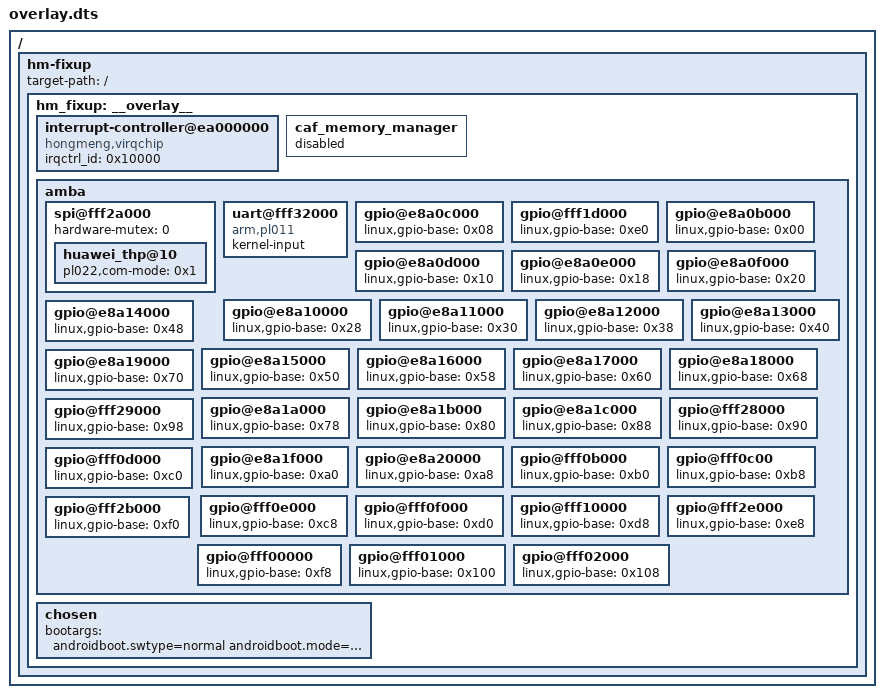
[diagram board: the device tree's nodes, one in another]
/dts-v1/;
/plugin/;

/* override conflict kirin980_chip_cs entries */
/ {
	hm-fixup {
		target-path = "/";
		hm_fixup: __overlay__ {};
	};
};

&hm_fixup {
	/* disable GIC to avoid hmkernel probe it */
	interrupt-controller@ea000000 {
		compatible = "hongmeng,virqchip";
		/* the value must be positive and the same as
		 * irqctrl_id in kirin980.dts
		 */
		irqctrl_id = <0x10000>;
	};

	/* disable mem manger for mali */
	caf_memory_manager {
		status = "disabled";
	};

	amba {
		/* disable un-supported features in thp spi */
		spi@fff2a000 {
			hardware-mutex = <0>; /* disable hardware mutex for spi3 */
			huawei_thp@10 {
				/* use polling mode instead of dma */
				pl022,com-mode = <0x1>;
			};
		};

		/* config uart6 as kernel-input */
		uart@fff32000 {
			compatible = "arm,pl011", "arm,pl011,uart";
			kernel-input;
		};

		/* config gpio base for backlight */
		gpio@e8a0c000 {
			linux,gpio-base = <0x08>;
		};

		gpio@fff1d000 {
			linux,gpio-base = <0xe0>;
		};

		/* config gpio base */
		gpio@e8a0b000 {
			linux,gpio-base = <0x00>;
		};

		gpio@e8a0d000 {
			linux,gpio-base = <0x10>;
		};

		gpio@e8a0e000 {
			linux,gpio-base = <0x18>;
		};

		gpio@e8a0f000 {
			linux,gpio-base = <0x20>;
		};

		gpio@e8a10000 {
			linux,gpio-base = <0x28>;
		};

		gpio@e8a11000 {
			linux,gpio-base = <0x30>;
		};

		gpio@e8a12000 {
			linux,gpio-base = <0x38>;
		};

		gpio@e8a13000 {
			linux,gpio-base = <0x40>;
		};

		gpio@e8a14000 {
			linux,gpio-base = <0x48>;
		};

		gpio@e8a15000 {
			linux,gpio-base = <0x50>;
		};

		gpio@e8a16000 {
			linux,gpio-base = <0x58>;
		};

		gpio@e8a17000 {
			linux,gpio-base = <0x60>;
		};

		gpio@e8a18000 {
			linux,gpio-base = <0x68>;
		};

		gpio@e8a19000 {
			linux,gpio-base = <0x70>;
		};

		gpio@e8a1a000 {
			linux,gpio-base = <0x78>;
		};

		gpio@e8a1b000 {
			linux,gpio-base = <0x80>;
		};

		gpio@e8a1c000 {
			linux,gpio-base = <0x88>;
		};

		gpio@fff28000 {
			linux,gpio-base = <0x90>;
		};

		gpio@fff29000 {
			linux,gpio-base = <0x98>;
		};

		gpio@e8a1f000 {
			linux,gpio-base = <0xa0>;
		};

		gpio@e8a20000 {
			linux,gpio-base = <0xa8>;
		};

		gpio@fff0b000 {
			linux,gpio-base = <0xb0>;
		};

		gpio@fff0c00 {
			linux,gpio-base = <0xb8>;
		};

		gpio@fff0d000 {
			linux,gpio-base = <0xc0>;
		};

		gpio@fff0e000 {
			linux,gpio-base = <0xc8>;
		};

		gpio@fff0f000 {
			linux,gpio-base = <0xd0>;
		};

		gpio@fff10000 {
			linux,gpio-base = <0xd8>;
		};

		gpio@fff2e000 {
			linux,gpio-base = <0xe8>;
		};

		gpio@fff2b000 {
			linux,gpio-base = <0xf0>;
		};

		gpio@fff00000 {
			linux,gpio-base = <0xf8>;
		};

		gpio@fff01000 {
			linux,gpio-base = <0x100>;
		};

		gpio@fff02000 {
			linux,gpio-base = <0x108>;
		};
	};
    chosen {
        bootargs = "androidboot.swtype=normal androidboot.mode=normal himntn=111101111110111010011111101001100010011010001";
    };
};
